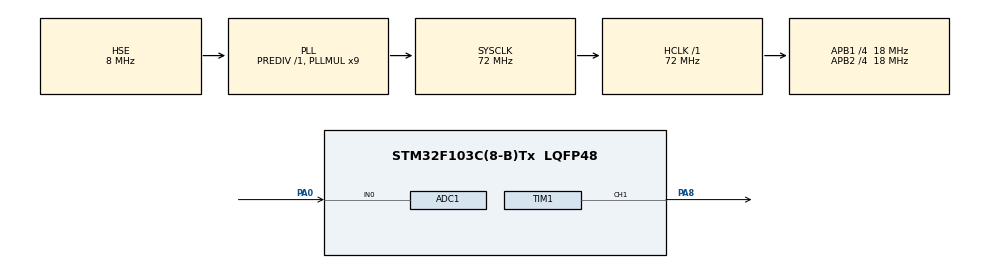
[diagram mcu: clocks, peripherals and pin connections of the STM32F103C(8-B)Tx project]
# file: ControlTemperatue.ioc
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ADC1.Channel-0\#ChannelRegularConversion=ADC_CHANNEL_0
ADC1.ContinuousConvMode=ENABLE
ADC1.InjNumberOfConversion=0
ADC1.NbrOfConversionFlag=1
ADC1.Rank-0\#ChannelRegularConversion=1
ADC1.SamplingTime-0\#ChannelRegularConversion=ADC_SAMPLETIME_41CYCLES_5
ADC1.master=1
Mcu.Family=STM32F1
Mcu.Name=STM32F103C(8-B)Tx
Mcu.Package=LQFP48
NVIC.PriorityGroup=NVIC_PRIORITYGROUP_4
NVIC.RCC_IRQn=true\:0\:0\:false\:false\:true
NVIC.TIM2_IRQn=true\:0\:0\:false\:false\:true
PA0-WKUP.Signal=ADCx_IN0
PA13.Mode=Serial_Wire
PA13.Signal=SYS_JTMS-SWDIO
PA14.Mode=Serial_Wire
PA14.Signal=SYS_JTCK-SWCLK
PA8.Signal=S_TIM1_CH1
PD0-OSC_IN.Mode=HSE-External-Oscillator
PD0-OSC_IN.Signal=RCC_OSC_IN
PD1-OSC_OUT.Mode=HSE-External-Oscillator
PD1-OSC_OUT.Signal=RCC_OSC_OUT
ProjectManager.HeapSize=0x200
ProjectManager.StackSize=0x400
ProjectManager.TargetToolchain=MDK-ARM V5
RCC.AHBFreq_Value=72000000
RCC.APB1CLKDivider=RCC_HCLK_DIV4
RCC.APB1Freq_Value=18000000
RCC.APB1TimFreq_Value=36000000
RCC.APB2CLKDivider=RCC_HCLK_DIV4
RCC.APB2Freq_Value=18000000
RCC.APB2TimFreq_Value=36000000
RCC.HCLKFreq_Value=72000000
RCC.HSIState=RCC_HSI_ON
RCC.PLLMUL=RCC_PLL_MUL9
RCC.PLLSourceVirtual=RCC_PLLSOURCE_HSE
RCC.SYSCLKFreq_VALUE=72000000
RCC.SYSCLKSource=RCC_SYSCLKSOURCE_PLLCLK
RCC.USBFreq_Value=72000000
SH.ADCx_IN0.0=ADC1_IN0,IN0
SH.S_TIM1_CH1.0=TIM1_CH1,PWM Generation1 CH1
TIM1.Period=99
TIM1.Prescaler=360
TIM2.Period=99
TIM2.Prescaler=36000
VP_TIM1_VS_ClockSourceINT.Mode=Internal
VP_TIM2_VS_ClockSourceINT.Mode=Internal
board=ControlTemperatue

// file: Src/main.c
/**
  ******************************************************************************
  * File Name          : main.c
  * Description        : Main program body
  ******************************************************************************
  *
  * COPYRIGHT(c) 2021 STMicroelectronics
  *
  * Redistribution and use in source and binary forms, with or without modification,
  * are permitted provided that the following conditions are met:
  *   1. Redistributions of source code must retain the above copyright notice,
  *      this list of conditions and the following disclaimer.
  *   2. Redistributions in binary form must reproduce the above copyright notice,
  *      this list of conditions and the following disclaimer in the documentation
  *      and/or other materials provided with the distribution.
  *   3. Neither the name of STMicroelectronics nor the names of its contributors
  *      may be used to endorse or promote products derived from this software
  *      without specific prior written permission.
  *
  * THIS SOFTWARE IS PROVIDED BY THE COPYRIGHT HOLDERS AND CONTRIBUTORS "AS IS"
  * AND ANY EXPRESS OR IMPLIED WARRANTIES, INCLUDING, BUT NOT LIMITED TO, THE
  * IMPLIED WARRANTIES OF MERCHANTABILITY AND FITNESS FOR A PARTICULAR PURPOSE ARE
  * DISCLAIMED. IN NO EVENT SHALL THE COPYRIGHT HOLDER OR CONTRIBUTORS BE LIABLE
  * FOR ANY DIRECT, INDIRECT, INCIDENTAL, SPECIAL, EXEMPLARY, OR CONSEQUENTIAL
  * DAMAGES (INCLUDING, BUT NOT LIMITED TO, PROCUREMENT OF SUBSTITUTE GOODS OR
  * SERVICES; LOSS OF USE, DATA, OR PROFITS; OR BUSINESS INTERRUPTION) HOWEVER
  * CAUSED AND ON ANY THEORY OF LIABILITY, WHETHER IN CONTRACT, STRICT LIABILITY,
  * OR TORT (INCLUDING NEGLIGENCE OR OTHERWISE) ARISING IN ANY WAY OUT OF THE USE
  * OF THIS SOFTWARE, EVEN IF ADVISED OF THE POSSIBILITY OF SUCH DAMAGE.
  *
  ******************************************************************************
  */
#include "stm32f1xx_hal.h"

/* USER CODE BEGIN Includes */
#include "math.h"
/* USER CODE END Includes */

ADC_HandleTypeDef hadc1;

TIM_HandleTypeDef htim1;
TIM_HandleTypeDef htim2;

/* USER CODE BEGIN PV */
/* Private variables ---------------------------------------------------------*/
volatile float value_Temperatue;
float valuuint16_te1;
float res2,temp,tr,temp_set=100, loi,loi_tr, i_loi=0,dloi=0;
float res1 = 10000;
float kp =0.2,kd=0.05,ki=0.003;
int pwm=0;
/* USER CODE END PV */

void SystemClock_Config(void);
static void MX_GPIO_Init(void);
static void MX_ADC1_Init(void);
static void MX_TIM1_Init(void);
static void MX_TIM2_Init(void);

void HAL_TIM_MspPostInit(TIM_HandleTypeDef *htim);

/* USER CODE BEGIN PFP */
/* Private function prototypes -----------------------------------------------*/
	void HAL_TIM_PeriodElapsedCallback(TIM_HandleTypeDef *htim);
	void convert_valueTemperatue(void);
/* USER CODE END PFP */

int main(void)
{

  /* MCU Configuration----------------------------------------------------------*/

  /* Reset of all peripherals, Initializes the Flash interface and the Systick. */
  HAL_Init();

  /* Configure the system clock */
  SystemClock_Config();

  /* Initialize all configured peripherals */
  MX_GPIO_Init();
  MX_ADC1_Init();
  MX_TIM1_Init();
  MX_TIM2_Init();

  /* USER CODE BEGIN 2 */
	HAL_ADC_Start(&hadc1);
	HAL_TIM_Base_Start_IT(&htim2);
  HAL_TIM_PWM_Start(&htim1,TIM_CHANNEL_1);
  /* USER CODE END 2 */

  /* Infinite loop */
  while (1)
  {

  /* USER CODE BEGIN 3 */
		             convert_valueTemperatue();
						if(temp_set>temp)
						{
								 loi=temp_set-temp;
								 i_loi=i_loi+loi;
										if(i_loi>200)i_loi=200;
						     dloi=loi_tr-loi;
								 pwm = pwm + kp*loi +   ki*i_loi +  kd*dloi;
								 if(pwm>100)pwm=100;
		            __HAL_TIM_SET_COMPARE(&htim1,TIM_CHANNEL_1,pwm);
								 HAL_TIM_PWM_Start(&htim1,TIM_CHANNEL_1);
								 loi_tr=loi;
		             HAL_Delay(50);
						}
						else
						{
								 loi=temp - temp_set;
								 i_loi=i_loi+loi;
										if(i_loi>200)i_loi=200;
						     dloi=loi_tr-loi;
								 pwm = pwm - kp*loi +   ki*i_loi +  kd*dloi;
								 if(pwm<0) pwm=0;
		            __HAL_TIM_SET_COMPARE(&htim1,TIM_CHANNEL_1,pwm);
								 HAL_TIM_PWM_Start(&htim1,TIM_CHANNEL_1);
								 loi_tr=loi;
		             HAL_Delay(50);
						}

  }
  /* USER CODE END 3 */

}

/** System Clock Configuration
*/
void SystemClock_Config(void)
{

  RCC_OscInitTypeDef RCC_OscInitStruct;
  RCC_ClkInitTypeDef RCC_ClkInitStruct;
  RCC_PeriphCLKInitTypeDef PeriphClkInit;

  RCC_OscInitStruct.OscillatorType = RCC_OSCILLATORTYPE_HSE;
  RCC_OscInitStruct.HSEState = RCC_HSE_ON;
  RCC_OscInitStruct.HSEPredivValue = RCC_HSE_PREDIV_DIV1;
  RCC_OscInitStruct.PLL.PLLState = RCC_PLL_ON;
  RCC_OscInitStruct.PLL.PLLSource = RCC_PLLSOURCE_HSE;
  RCC_OscInitStruct.PLL.PLLMUL = RCC_PLL_MUL9;
  HAL_RCC_OscConfig(&RCC_OscInitStruct);

  RCC_ClkInitStruct.ClockType = RCC_CLOCKTYPE_HCLK|RCC_CLOCKTYPE_SYSCLK
                              |RCC_CLOCKTYPE_PCLK1|RCC_CLOCKTYPE_PCLK2;
  RCC_ClkInitStruct.SYSCLKSource = RCC_SYSCLKSOURCE_PLLCLK;
  RCC_ClkInitStruct.AHBCLKDivider = RCC_SYSCLK_DIV1;
  RCC_ClkInitStruct.APB1CLKDivider = RCC_HCLK_DIV4;
  RCC_ClkInitStruct.APB2CLKDivider = RCC_HCLK_DIV4;
  HAL_RCC_ClockConfig(&RCC_ClkInitStruct, FLASH_LATENCY_2);

  PeriphClkInit.PeriphClockSelection = RCC_PERIPHCLK_ADC;
  PeriphClkInit.AdcClockSelection = RCC_ADCPCLK2_DIV2;
  HAL_RCCEx_PeriphCLKConfig(&PeriphClkInit);

  HAL_SYSTICK_Config(HAL_RCC_GetHCLKFreq()/1000);

  HAL_SYSTICK_CLKSourceConfig(SYSTICK_CLKSOURCE_HCLK);

  /* SysTick_IRQn interrupt configuration */
  HAL_NVIC_SetPriority(SysTick_IRQn, 0, 0);
}

/* ADC1 init function */
void MX_ADC1_Init(void)
{

  ADC_ChannelConfTypeDef sConfig;

    /**Common config
    */
  hadc1.Instance = ADC1;
  hadc1.Init.ScanConvMode = ADC_SCAN_DISABLE;
  hadc1.Init.ContinuousConvMode = ENABLE;
  hadc1.Init.DiscontinuousConvMode = DISABLE;
  hadc1.Init.ExternalTrigConv = ADC_SOFTWARE_START;
  hadc1.Init.DataAlign = ADC_DATAALIGN_RIGHT;
  hadc1.Init.NbrOfConversion = 1;
  HAL_ADC_Init(&hadc1);

    /**Configure Regular Channel
    */
  sConfig.Channel = ADC_CHANNEL_0;
  sConfig.Rank = 1;
  sConfig.SamplingTime = ADC_SAMPLETIME_41CYCLES_5;
  HAL_ADC_ConfigChannel(&hadc1, &sConfig);

}

/* TIM1 init function */
void MX_TIM1_Init(void)
{

  TIM_ClockConfigTypeDef sClockSourceConfig;
  TIM_MasterConfigTypeDef sMasterConfig;
  TIM_BreakDeadTimeConfigTypeDef sBreakDeadTimeConfig;
  TIM_OC_InitTypeDef sConfigOC;

  htim1.Instance = TIM1;
  htim1.Init.Prescaler = 360;
  htim1.Init.CounterMode = TIM_COUNTERMODE_UP;
  htim1.Init.Period = 99;
  htim1.Init.ClockDivision = TIM_CLOCKDIVISION_DIV1;
  htim1.Init.RepetitionCounter = 0;
  HAL_TIM_Base_Init(&htim1);

  sClockSourceConfig.ClockSource = TIM_CLOCKSOURCE_INTERNAL;
  HAL_TIM_ConfigClockSource(&htim1, &sClockSourceConfig);

  HAL_TIM_PWM_Init(&htim1);

  sMasterConfig.MasterOutputTrigger = TIM_TRGO_RESET;
  sMasterConfig.MasterSlaveMode = TIM_MASTERSLAVEMODE_DISABLE;
  HAL_TIMEx_MasterConfigSynchronization(&htim1, &sMasterConfig);

  sBreakDeadTimeConfig.OffStateRunMode = TIM_OSSR_DISABLE;
  sBreakDeadTimeConfig.OffStateIDLEMode = TIM_OSSI_DISABLE;
  sBreakDeadTimeConfig.LockLevel = TIM_LOCKLEVEL_OFF;
  sBreakDeadTimeConfig.DeadTime = 0;
  sBreakDeadTimeConfig.BreakState = TIM_BREAK_DISABLE;
  sBreakDeadTimeConfig.BreakPolarity = TIM_BREAKPOLARITY_HIGH;
  sBreakDeadTimeConfig.AutomaticOutput = TIM_AUTOMATICOUTPUT_DISABLE;
  HAL_TIMEx_ConfigBreakDeadTime(&htim1, &sBreakDeadTimeConfig);

  sConfigOC.OCMode = TIM_OCMODE_PWM1;
  sConfigOC.Pulse = 0;
  sConfigOC.OCPolarity = TIM_OCPOLARITY_HIGH;
  sConfigOC.OCNPolarity = TIM_OCNPOLARITY_HIGH;
  sConfigOC.OCFastMode = TIM_OCFAST_DISABLE;
  sConfigOC.OCIdleState = TIM_OCIDLESTATE_RESET;
  sConfigOC.OCNIdleState = TIM_OCNIDLESTATE_RESET;
  HAL_TIM_PWM_ConfigChannel(&htim1, &sConfigOC, TIM_CHANNEL_1);

  HAL_TIM_MspPostInit(&htim1);

}

/* TIM2 init function */
void MX_TIM2_Init(void)
{

  TIM_ClockConfigTypeDef sClockSourceConfig;
  TIM_MasterConfigTypeDef sMasterConfig;

  htim2.Instance = TIM2;
  htim2.Init.Prescaler = 36000;
  htim2.Init.CounterMode = TIM_COUNTERMODE_UP;
  htim2.Init.Period = 99;
  htim2.Init.ClockDivision = TIM_CLOCKDIVISION_DIV1;
  HAL_TIM_Base_Init(&htim2);

  sClockSourceConfig.ClockSource = TIM_CLOCKSOURCE_INTERNAL;
  HAL_TIM_ConfigClockSource(&htim2, &sClockSourceConfig);

  sMasterConfig.MasterOutputTrigger = TIM_TRGO_RESET;
  sMasterConfig.MasterSlaveMode = TIM_MASTERSLAVEMODE_DISABLE;
  HAL_TIMEx_MasterConfigSynchronization(&htim2, &sMasterConfig);

}

/** Configure pins as
        * Analog
        * Input
        * Output
        * EVENT_OUT
        * EXTI
*/
void MX_GPIO_Init(void)
{

  /* GPIO Ports Clock Enable */
  __HAL_RCC_GPIOD_CLK_ENABLE();
  __HAL_RCC_GPIOA_CLK_ENABLE();

}

/* USER CODE BEGIN 4 */
void HAL_TIM_PeriodElapsedCallback(TIM_HandleTypeDef *htim)
{
	if(htim->Instance==htim2.Instance)
		{
		value_Temperatue = HAL_ADC_GetValue(&hadc1);
		}

	}

	void convert_valueTemperatue()
		{
 tr= (4095/value_Temperatue)-1;
 res2 = 10000*tr;       // gia tri nhiet tro
 temp = res2/100000;
 temp = log(temp);
 temp = temp / 3950;
 temp = temp + (1/298.15);
 temp = 1.0 / temp;
 temp = temp - 273.15;

		}
/* USER CODE END 4 */

/************************ (C) COPYRIGHT STMicroelectronics *****END OF FILE****/
